AUTOSAR XML (schema 00047)
package /Components
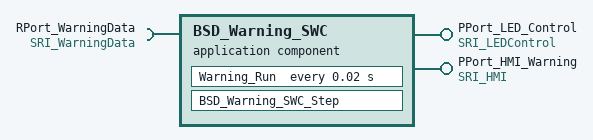
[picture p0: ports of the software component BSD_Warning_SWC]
  application sw component type BSD_Warning_SWC
    require port RPort_WarningData: nonqueued-receiver-com-spec{data-element=Warning_Status, init-value=0}, required-interface=SRI_WarningData
    provide port PPort_LED_Control: provided-interface=SRI_LEDControl
      provided-com-specs:
        data-element=LED_Left, init-value=0
        data-element=LED_Right, init-value=0
        data-element=Buzzer_Active, init-value=0
    provide port PPort_HMI_Warning: nonqueued-sender-com-spec{data-element=HMI_Display, init-value=0}, provided-interface=SRI_HMI
    behavior BSD_Warning_SWC_IB: handle-termination-and-restart=NO-SUPPORT
      timing event Event_BSD_Warning_SWC_Step: start-on-event=Warning_Run, period=0.02
      init event Warning_init: start-on-event=BSD_Warning_SWC_Step
      runnable BSD_Warning_SWC_Step
      runnable Warning_Run
        data-read-access:
          access IN_RPort_WarningData_Warning_Status: accessed-variable=RPort_WarningData.Warning_Status
        data-write-access:
          4 x access:
            OUT_PPort_LED_Control_LED_Left: accessed-variable=PPort_LED_Control.LED_Left
            OUT_PPort_LED_Control_LED_Right: accessed-variable=PPort_LED_Control.LED_Right
            OUT_PPort_LED_Control_Buzzer_Active: accessed-variable=PPort_LED_Control.Buzzer_Active
            OUT_PPort_HMI_Warning_HMI_Display: accessed-variable=PPort_HMI_Warning.HMI_Display
